# M440 register map
File version: 0.1
Registers are 32-bit, read-write, reset 0x0 unless marked. A register's access mark holds for its fields unless they carry their own. Offsets are from the block's base; [hi:lo] are bit positions; {n}, {i} and the like mark numbered series.

## PE — Port E
Base 0x400C0400
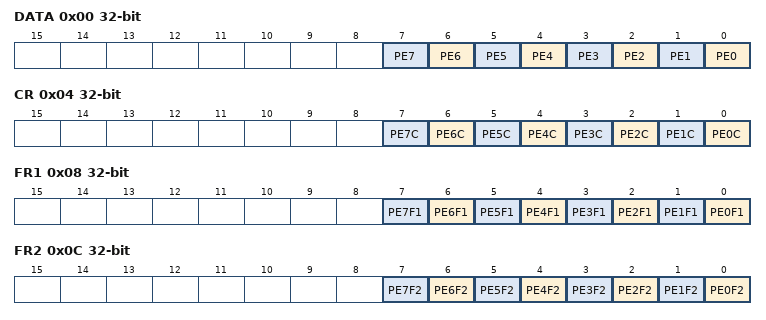
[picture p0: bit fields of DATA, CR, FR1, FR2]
0x00 DATA — Port E Data Register
  [n] PE{n} (n=0..7)
0x04 CR — Port E Output Control Register
  [n] PE{n}C (n=0..7)
0x08 FR1 — Port E Function Register 1
  [n] PE{n}F1 (n=0..7)
0x0C FR2 — Port E Function Register 2
  [n] PE{n}F2 (n=0..7)
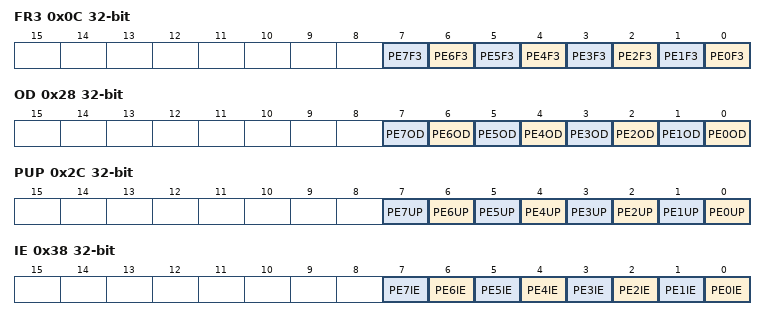
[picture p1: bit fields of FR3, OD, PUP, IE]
0x0C FR3 — Port E Function Register 3
  [n] PE{n}F3 (n=0..7)
0x28 OD — Port E Open Drain Control Register
  [n] PE{n}OD (n=0..7)
0x2C PUP — Port E Pull-up Control Register
  [n] PE{n}UP (n=0..7)
0x38 IE — Port E Input Control Register
  [n] PE{n}IE (n=0..7)

## PF — Port F
Base 0x400C0500
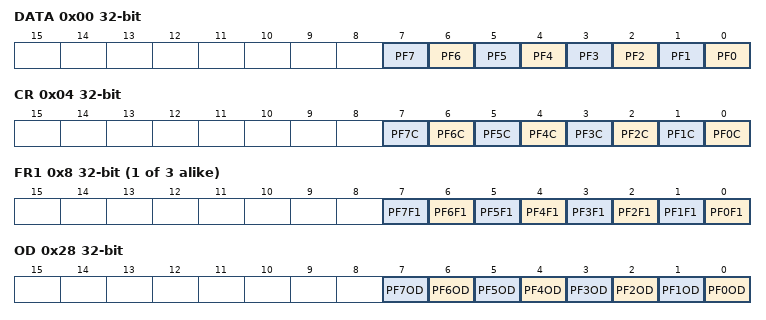
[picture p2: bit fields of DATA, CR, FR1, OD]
0x00 DATA — Port F Data Register
  [n] PF{n} (n=0..7)
0x04 CR — Port F Output Control Register
  [n] PF{n}C (n=0..7)
{0x4+4i} FR{i} (i=1..3) — Port F Function Register {i}
  [n] PF{n}F{i} (n=0..7)
0x28 OD — Port F Open Drain Control Register
  [n] PF{n}OD (n=0..7)
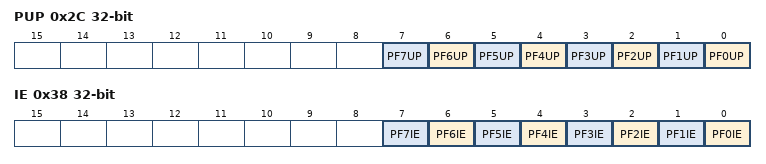
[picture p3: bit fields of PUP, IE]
0x2C PUP — Port F Pull-up Control Register
  [n] PF{n}UP (n=0..7)
0x38 IE — Port F Input Control Register
  [n] PF{n}IE (n=0..7)

## PG — Port G
Base 0x400C0600
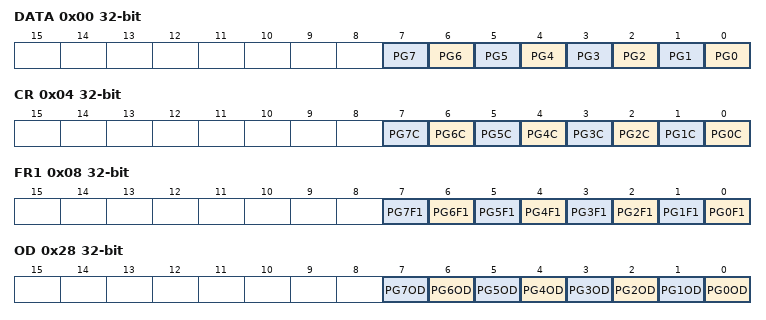
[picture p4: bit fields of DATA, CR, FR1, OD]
0x00 DATA — Port G Data Register
  [n] PG{n} (n=0..7)
0x04 CR — Port G Output Control Register
  [n] PG{n}C (n=0..7)
0x08 FR1 — Port G Function Register 1
  [n] PG{n}F1 (n=0..7)
0x28 OD — Port G Open Drain Control Register
  [n] PG{n}OD (n=0..7)
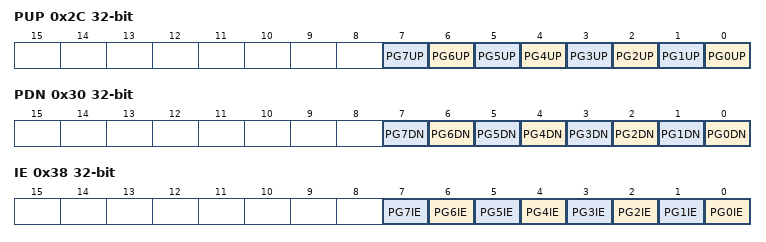
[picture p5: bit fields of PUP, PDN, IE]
0x2C PUP — Port G Pull-up Control Register
  [n] PG{n}UP (n=0..7)
0x30 PDN — Port G Pull-down Control Register
  [n] PG{n}DN (n=0..7)
0x38 IE — Port G Input Control Register
  [n] PG{n}IE (n=0..7)

## PH — Port H
Base 0x400C0700
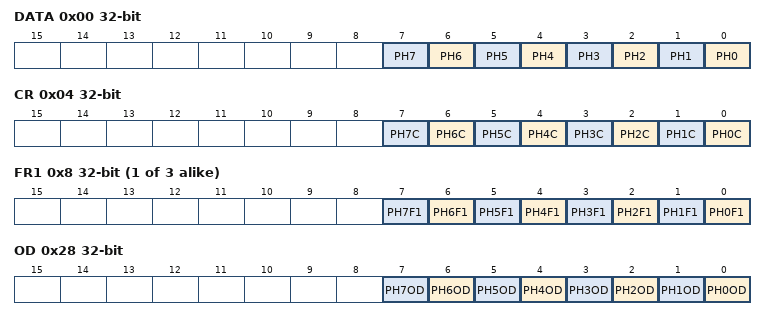
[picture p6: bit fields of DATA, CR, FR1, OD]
0x00 DATA — Port H Data Register
  [n] PH{n} (n=0..7)
0x04 CR — Port H Output Control Register
  [n] PH{n}C (n=0..7)
{0x4+4i} FR{i} (i=1..3) — Port H Function Register {i}
  [n] PH{n}F{i} (n=0..7)
0x28 OD — Port H Open Drain Control Register
  [n] PH{n}OD (n=0..7)
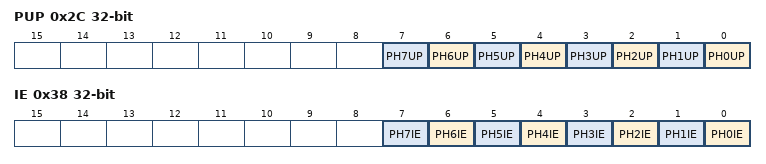
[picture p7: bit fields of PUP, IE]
0x2C PUP — Port H Pull-up Control Register
  [n] PH{n}UP (n=0..7)
0x38 IE — Port H Input Control Register
  [n] PH{n}IE (n=0..7)

## PJ — Port J
Base 0x400C0800
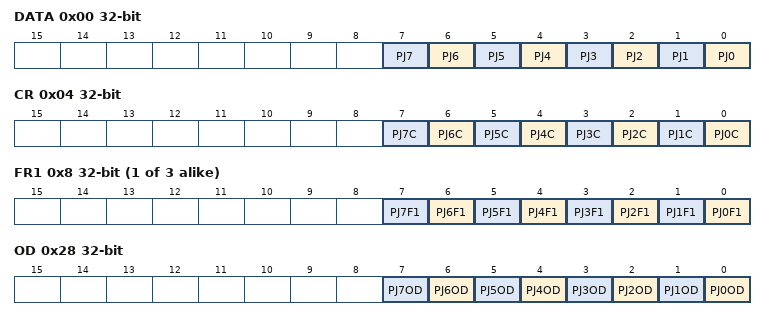
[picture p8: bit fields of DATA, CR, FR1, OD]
0x00 DATA — Port J Data Register
  [n] PJ{n} (n=0..7)
0x04 CR — Port J Output Control Register
  [n] PJ{n}C (n=0..7)
{0x4+4i} FR{i} (i=1..3) — Port J Function Register {i}
  [n] PJ{n}F{i} (n=0..7)
0x28 OD — Port J Open Drain Control Register
  [n] PJ{n}OD (n=0..7)
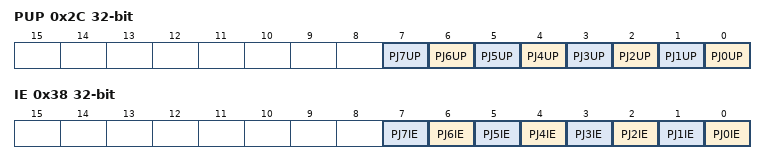
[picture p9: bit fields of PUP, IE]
0x2C PUP — Port J Pull-up Control Register
  [n] PJ{n}UP (n=0..7)
0x38 IE — Port J Input Control Register
  [n] PJ{n}IE (n=0..7)

## PK — Port K
Base 0x400C0900
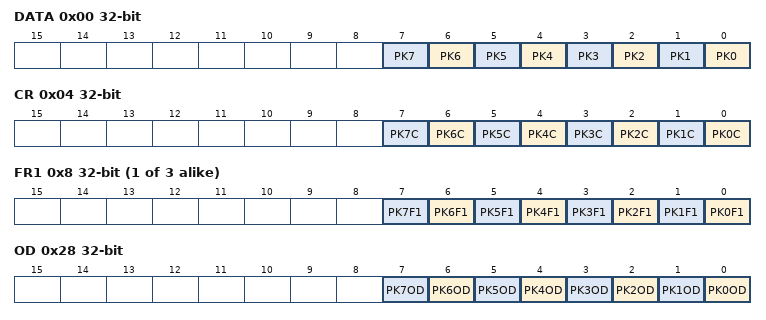
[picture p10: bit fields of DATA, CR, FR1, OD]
0x00 DATA — Port K Data Register
  [n] PK{n} (n=0..7)
0x04 CR — Port K Output Control Register
  [n] PK{n}C (n=0..7)
{0x4+4i} FR{i} (i=1..3) — Port K Function Register {i}
  [n] PK{n}F{i} (n=0..7)
0x28 OD — Port K Open Drain Control Register
  [n] PK{n}OD (n=0..7)
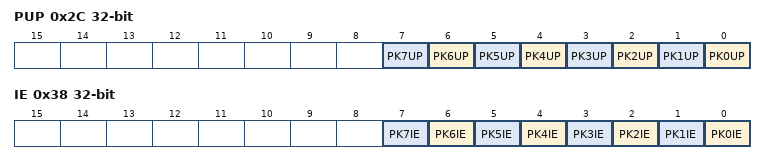
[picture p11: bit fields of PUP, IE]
0x2C PUP — Port K Pull-up Control Register
  [n] PK{n}UP (n=0..7)
0x38 IE — Port K Input Control Register
  [n] PK{n}IE (n=0..7)

## PL — Port L
Base 0x400C0A00
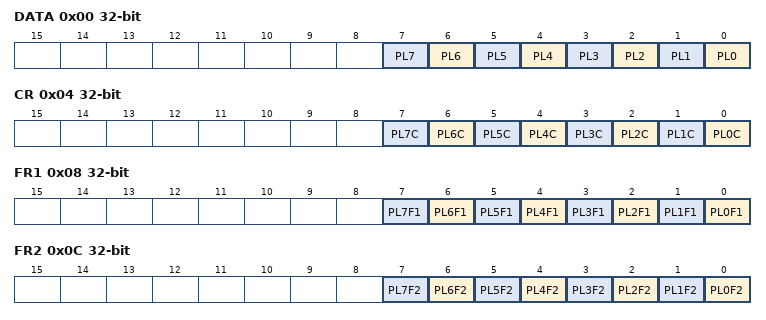
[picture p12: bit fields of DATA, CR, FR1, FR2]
0x00 DATA — Port L Data Register
  [n] PL{n} (n=0..7)
0x04 CR — Port L Output Control Register
  [n] PL{n}C (n=0..7)
0x08 FR1 — Port L Function Register 1
  [n] PL{n}F1 (n=0..7)
0x0C FR2 — Port L Function Register 2
  [n] PL{n}F2 (n=0..7)
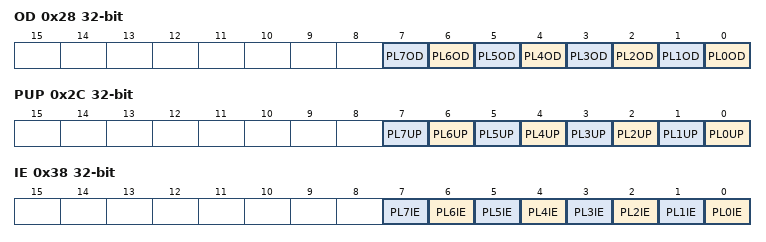
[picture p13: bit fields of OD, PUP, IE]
0x28 OD — Port L Open Drain Control Register
  [n] PL{n}OD (n=0..7)
0x2C PUP — Port L Pull-up Control Register
  [n] PL{n}UP (n=0..7)
0x38 IE — Port L Input Control Register
  [n] PL{n}IE (n=0..7)

## PM — Port M
Base 0x400C0B00
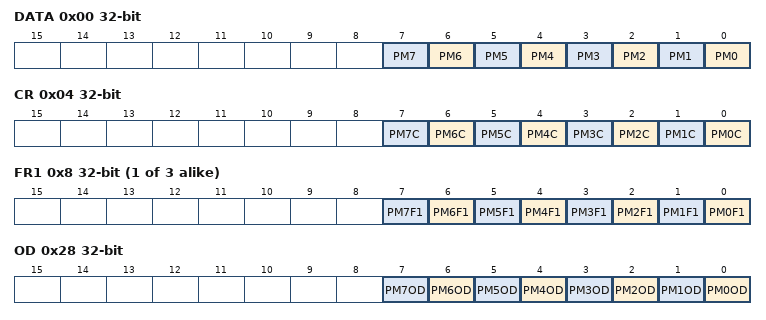
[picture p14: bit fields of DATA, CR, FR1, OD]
0x00 DATA — Port M Data Register
  [n] PM{n} (n=0..7)
0x04 CR — Port M Output Control Register
  [n] PM{n}C (n=0..7)
{0x4+4i} FR{i} (i=1..3) — Port M Function Register {i}
  [n] PM{n}F{i} (n=0..7)
0x28 OD — Port M Open Drain Control Register
  [n] PM{n}OD (n=0..7)
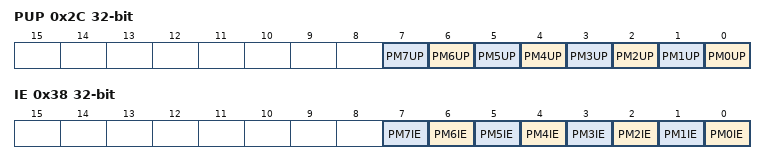
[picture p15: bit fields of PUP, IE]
0x2C PUP — Port M Pull-up Control Register
  [n] PM{n}UP (n=0..7)
0x38 IE — Port M Input Control Register
  [n] PM{n}IE (n=0..7)
